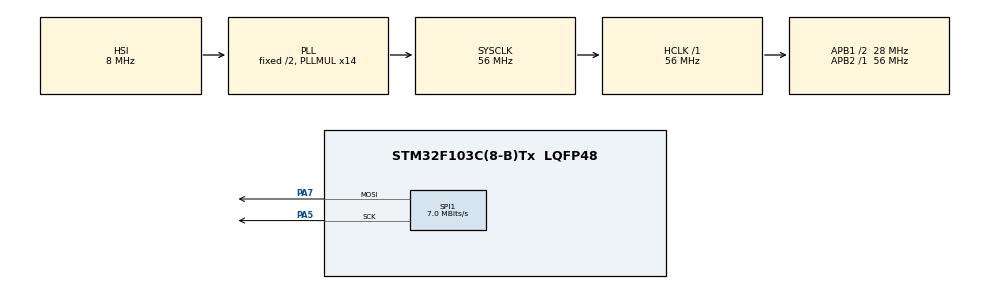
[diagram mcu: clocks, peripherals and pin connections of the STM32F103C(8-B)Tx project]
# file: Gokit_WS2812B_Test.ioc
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Dma.Request0=SPI1_TX
Dma.SPI1_TX.0.Direction=DMA_MEMORY_TO_PERIPH
Dma.SPI1_TX.0.Instance=DMA1_Channel3
Dma.SPI1_TX.0.MemDataAlignment=DMA_MDATAALIGN_BYTE
Dma.SPI1_TX.0.MemInc=DMA_MINC_ENABLE
Dma.SPI1_TX.0.Mode=DMA_NORMAL
Dma.SPI1_TX.0.PeriphDataAlignment=DMA_PDATAALIGN_BYTE
Dma.SPI1_TX.0.PeriphInc=DMA_PINC_DISABLE
Dma.SPI1_TX.0.Priority=DMA_PRIORITY_VERY_HIGH
Mcu.Family=STM32F1
Mcu.Name=STM32F103C(8-B)Tx
Mcu.Package=LQFP48
NVIC.DMA1_Channel3_IRQn=true\:0\:0\:false\:false\:true
NVIC.PriorityGroup=NVIC_PRIORITYGROUP_4
PA13.Mode=Serial_Wire
PA13.Signal=SYS_JTMS-SWDIO
PA14.Mode=Serial_Wire
PA14.Signal=SYS_JTCK-SWCLK
PA5.Mode=TX_Only_Simplex_Unidirect_Master
PA5.Signal=SPI1_SCK
PA7.Mode=TX_Only_Simplex_Unidirect_Master
PA7.Signal=SPI1_MOSI
PD0-OSC_IN.Mode=HSE-External-Oscillator
PD0-OSC_IN.Signal=RCC_OSC_IN
PD1-OSC_OUT.Mode=HSE-External-Oscillator
PD1-OSC_OUT.Signal=RCC_OSC_OUT
ProjectManager.HeapSize=0x800
ProjectManager.StackSize=0x800
ProjectManager.TargetToolchain=EWARM
RCC.AHBFreq_Value=56000000
RCC.APB1CLKDivider=RCC_HCLK_DIV2
RCC.APB1Freq_Value=28000000
RCC.APB1TimFreq_Value=56000000
RCC.APB2Freq_Value=56000000
RCC.APB2TimFreq_Value=56000000
RCC.HCLKFreq_Value=56000000
RCC.PLLMUL=RCC_PLL_MUL14
RCC.SYSCLKFreq_VALUE=56000000
RCC.SYSCLKSource=RCC_SYSCLKSOURCE_PLLCLK
RCC.USBFreq_Value=56000000
SPI1.BaudRatePrescaler=SPI_BAUDRATEPRESCALER_8
SPI1.CalculateBaudRate=7.0 MBits/s
SPI1.DataSize=SPI_DATASIZE_8BIT
SPI1.Mode=SPI_MODE_MASTER
board=Gokit_WS2812B_Test

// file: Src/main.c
/**
  ******************************************************************************
  * File Name          : main.c
  * Description        : Main program body
  ******************************************************************************
  *
  * COPYRIGHT(c) 2017 STMicroelectronics
  *
  * Redistribution and use in source and binary forms, with or without modification,
  * are permitted provided that the following conditions are met:
  *   1. Redistributions of source code must retain the above copyright notice,
  *      this list of conditions and the following disclaimer.
  *   2. Redistributions in binary form must reproduce the above copyright notice,
  *      this list of conditions and the following disclaimer in the documentation
  *      and/or other materials provided with the distribution.
  *   3. Neither the name of STMicroelectronics nor the names of its contributors
  *      may be used to endorse or promote products derived from this software
  *      without specific prior written permission.
  *
  * THIS SOFTWARE IS PROVIDED BY THE COPYRIGHT HOLDERS AND CONTRIBUTORS "AS IS"
  * AND ANY EXPRESS OR IMPLIED WARRANTIES, INCLUDING, BUT NOT LIMITED TO, THE
  * IMPLIED WARRANTIES OF MERCHANTABILITY AND FITNESS FOR A PARTICULAR PURPOSE ARE
  * DISCLAIMED. IN NO EVENT SHALL THE COPYRIGHT HOLDER OR CONTRIBUTORS BE LIABLE
  * FOR ANY DIRECT, INDIRECT, INCIDENTAL, SPECIAL, EXEMPLARY, OR CONSEQUENTIAL
  * DAMAGES (INCLUDING, BUT NOT LIMITED TO, PROCUREMENT OF SUBSTITUTE GOODS OR
  * SERVICES; LOSS OF USE, DATA, OR PROFITS; OR BUSINESS INTERRUPTION) HOWEVER
  * CAUSED AND ON ANY THEORY OF LIABILITY, WHETHER IN CONTRACT, STRICT LIABILITY,
  * OR TORT (INCLUDING NEGLIGENCE OR OTHERWISE) ARISING IN ANY WAY OUT OF THE USE
  * OF THIS SOFTWARE, EVEN IF ADVISED OF THE POSSIBILITY OF SUCH DAMAGE.
  *
  ******************************************************************************
  */
#include "main.h"
#include "stm32f1xx_hal.h"
#include "dma.h"
#include "spi.h"
#include "gpio.h"

/* USER CODE BEGIN Includes */

#include "Adafruit_NeoPixel.h"

/* USER CODE END Includes */

/* USER CODE BEGIN PV */
/* Private variables ---------------------------------------------------------*/

/* USER CODE END PV */

void SystemClock_Config(void);
void Error_Handler(void);

/* USER CODE BEGIN PFP */
/* Private function prototypes -----------------------------------------------*/

/* USER CODE END PFP */

int main(void)
{

  /* MCU Configuration----------------------------------------------------------*/

  /* Reset of all peripherals, Initializes the Flash interface and the Systick. */
  HAL_Init();

  /* Configure the system clock */
  SystemClock_Config();

  /* Initialize all configured peripherals */
  MX_GPIO_Init();
  MX_DMA_Init();
  MX_SPI1_Init();

  /* USER CODE BEGIN 2 */

    WS2812B_Init();

    setAllPixelColor(255, 255, 255);
    HAL_Delay (2000);
    setAllPixelColor(255, 0, 0);
    HAL_Delay (2000);
    setAllPixelColor(0, 255, 0);
    HAL_Delay (2000);
    setAllPixelColor(0, 0, 255);
    HAL_Delay (2000);

    setAllPixelColor(0, 0, 0);
    HAL_Delay (500);

    setPixelColor(0, 0, 255, 0);
    HAL_Delay (1000);
    setPixelColor(2, 0, 0, 255);
    HAL_Delay (1000);
    setPixelColor(4, 255, 0, 0);
    HAL_Delay (1000);
    setPixelColor(6, 125, 125, 125);
    HAL_Delay (1000);
    setPixelColor(5, 0, 255, 0);
    HAL_Delay (500);
    setPixelColor(3, 0, 0, 255);
    HAL_Delay (500);
    setPixelColor(1, 255, 0, 0);
    HAL_Delay (500);

  /* USER CODE END 2 */

  /* Infinite loop */
  while (1)
  {

  /* USER CODE BEGIN 3 */
    WS2812B_Test();
  }
  /* USER CODE END 3 */

}

/** System Clock Configuration
*/
void SystemClock_Config(void)
{

  RCC_OscInitTypeDef RCC_OscInitStruct;
  RCC_ClkInitTypeDef RCC_ClkInitStruct;

    /**Initializes the CPU, AHB and APB busses clocks
    */
  RCC_OscInitStruct.OscillatorType = RCC_OSCILLATORTYPE_HSI;
  RCC_OscInitStruct.HSIState = RCC_HSI_ON;
  RCC_OscInitStruct.HSICalibrationValue = 16;
  RCC_OscInitStruct.PLL.PLLState = RCC_PLL_ON;
  RCC_OscInitStruct.PLL.PLLSource = RCC_PLLSOURCE_HSI_DIV2;
  RCC_OscInitStruct.PLL.PLLMUL = RCC_PLL_MUL14;
  if (HAL_RCC_OscConfig(&RCC_OscInitStruct) != HAL_OK)
  {
    Error_Handler();
  }

    /**Initializes the CPU, AHB and APB busses clocks
    */
  RCC_ClkInitStruct.ClockType = RCC_CLOCKTYPE_HCLK|RCC_CLOCKTYPE_SYSCLK
                              |RCC_CLOCKTYPE_PCLK1|RCC_CLOCKTYPE_PCLK2;
  RCC_ClkInitStruct.SYSCLKSource = RCC_SYSCLKSOURCE_PLLCLK;
  RCC_ClkInitStruct.AHBCLKDivider = RCC_SYSCLK_DIV1;
  RCC_ClkInitStruct.APB1CLKDivider = RCC_HCLK_DIV2;
  RCC_ClkInitStruct.APB2CLKDivider = RCC_HCLK_DIV1;

  if (HAL_RCC_ClockConfig(&RCC_ClkInitStruct, FLASH_LATENCY_2) != HAL_OK)
  {
    Error_Handler();
  }

    /**Configure the Systick interrupt time
    */
  HAL_SYSTICK_Config(HAL_RCC_GetHCLKFreq()/1000);

    /**Configure the Systick
    */
  HAL_SYSTICK_CLKSourceConfig(SYSTICK_CLKSOURCE_HCLK);

  /* SysTick_IRQn interrupt configuration */
  HAL_NVIC_SetPriority(SysTick_IRQn, 0, 0);
}

void Error_Handler(void)
{
  while(1)
  {
  }
}

/************************ (C) COPYRIGHT STMicroelectronics *****END OF FILE****/
